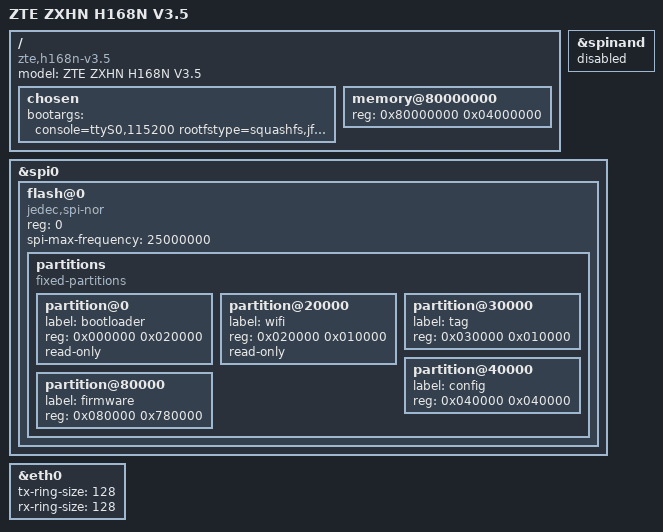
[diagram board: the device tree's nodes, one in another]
// SPDX-License-Identifier: GPL-2.0-or-later OR MIT
/dts-v1/;
#include "en751221.dtsi"

/ {
	model = "ZTE ZXHN H168N V3.5";
	compatible = "zte,h168n-v3.5", "econet,en751221";

	chosen {
		bootargs = "console=ttyS0,115200 rootfstype=squashfs,jffs2";
	};

	memory@80000000 {
		device_type = "memory";
		reg = <0x80000000 0x04000000>; /* Pinpoints exact 64MB RAM limit */
	};
};

/* Disable generic SPI NAND searching loops to stop kernel log errors */
&spinand {
	status = "disabled";
};

/* Target the physical onboard Winbond W25Q64 8MB Flash chip */
&spi0 {
	status = "okay";

	flash@0 {
		compatible = "jedec,spi-nor";
		reg = <0>;
		spi-max-frequency = <25000000>;

		partitions {
			compatible = "fixed-partitions";
			#address-cells = <1>;
			#size-cells = <1>;

			partition@0 {
				label = "bootloader";
				reg = <0x000000 0x020000>; /* 128KB Bootloader partition */
				read-only;
			};

			partition@20000 {
				label = "wifi";
				reg = <0x020000 0x010000>; /* 64KB Calibration sector */
				read-only;
			};

			partition@30000 {
				label = "tag";
				reg = <0x030000 0x010000>;
			};

			partition@40000 {
				label = "config";
				reg = <0x040000 0x040000>;
			};

			partition@80000 {
				label = "firmware";
				reg = <0x080000 0x780000>; /* Remaining 7.5MB allocated space */
			};
		};
	};
};

/* Restrict the Ethernet DMA drivers ring footprint to free up 15MB+ of RAM */
&eth0 {
	status = "okay";
	tx-ring-size = <128>; 
	rx-ring-size = <128>;
};
